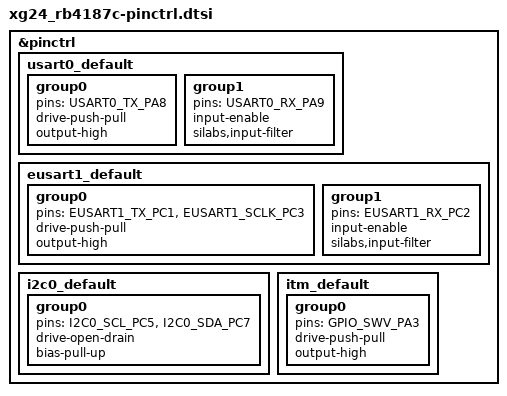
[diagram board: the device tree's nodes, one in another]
/*
 * Copyright (c) 2023 Antmicro <www.antmicro.com>
 * Copyright (c) 2025 Silicon Laboratories Inc.
 *
 * SPDX-License-Identifier: Apache-2.0
 */

#include <dt-bindings/pinctrl/silabs/xg24-pinctrl.h>

&pinctrl {
	usart0_default: usart0_default {
		group0 {
			pins = <USART0_TX_PA8>;
			drive-push-pull;
			output-high;
		};
		group1 {
			pins = <USART0_RX_PA9>;
			input-enable;
			silabs,input-filter;
		};
	};

	eusart1_default: eusart1_default {
		group0 {
			pins = <EUSART1_TX_PC1>, <EUSART1_SCLK_PC3>;
			drive-push-pull;
			output-high;
		};
		group1 {
			pins = <EUSART1_RX_PC2>;
			input-enable;
			silabs,input-filter;
		};
	};

	i2c0_default: i2c0_default {
		group0 {
			pins = <I2C0_SCL_PC5>, <I2C0_SDA_PC7>;
			drive-open-drain;
			bias-pull-up;
		};
	};

	itm_default: itm_default {
		group0 {
			pins = <GPIO_SWV_PA3>;
			drive-push-pull;
			output-high;
		};
	};
};
